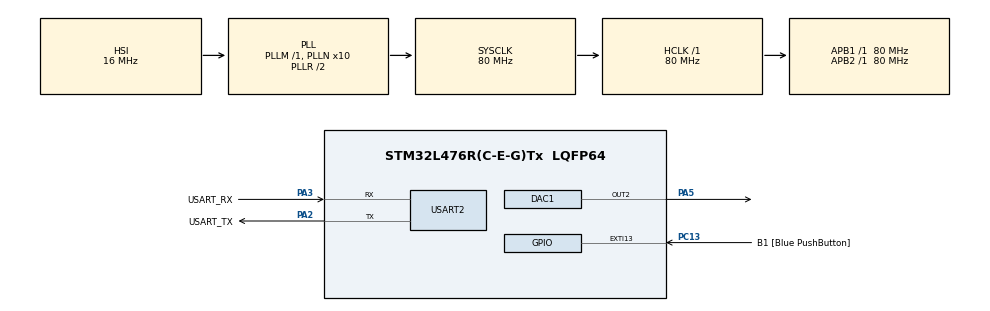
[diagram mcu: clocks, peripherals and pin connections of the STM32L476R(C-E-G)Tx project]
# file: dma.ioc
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DAC1.DAC_Channel-DAC_OUT2=DAC_CHANNEL_2
DAC1.DAC_Trigger-DAC_OUT2=DAC_TRIGGER_T6_TRGO
Dma.DAC_CH2.0.Direction=DMA_MEMORY_TO_PERIPH
Dma.DAC_CH2.0.Instance=DMA1_Channel4
Dma.DAC_CH2.0.MemDataAlignment=DMA_MDATAALIGN_BYTE
Dma.DAC_CH2.0.MemInc=DMA_MINC_ENABLE
Dma.DAC_CH2.0.Mode=DMA_CIRCULAR
Dma.DAC_CH2.0.PeriphDataAlignment=DMA_PDATAALIGN_BYTE
Dma.DAC_CH2.0.PeriphInc=DMA_PINC_DISABLE
Dma.DAC_CH2.0.Priority=DMA_PRIORITY_LOW
Dma.Request0=DAC_CH2
Mcu.Family=STM32L4
Mcu.Name=STM32L476R(C-E-G)Tx
Mcu.Package=LQFP64
NVIC.DMA1_Channel4_IRQn=true\:0\:0\:false\:false\:true\:false\:true
NVIC.PriorityGroup=NVIC_PRIORITYGROUP_4
NVIC.TIM6_DAC_IRQn=true\:0\:0\:false\:false\:true\:true\:true
PA13\ (JTMS-SWDIO).GPIO_Label=TMS
PA13\ (JTMS-SWDIO).Mode=Serial_Wire
PA13\ (JTMS-SWDIO).Signal=SYS_JTMS-SWDIO
PA14\ (JTCK-SWCLK).GPIO_Label=TCK
PA14\ (JTCK-SWCLK).Mode=Serial_Wire
PA14\ (JTCK-SWCLK).Signal=SYS_JTCK-SWCLK
PA2.GPIO_Label=USART_TX
PA2.GPIO_Mode=GPIO_MODE_AF_PP
PA2.GPIO_PuPd=GPIO_NOPULL
PA2.GPIO_Speed=GPIO_SPEED_FREQ_VERY_HIGH
PA2.Mode=Asynchronous
PA2.Signal=USART2_TX
PA3.GPIO_Label=USART_RX
PA3.GPIO_Mode=GPIO_MODE_AF_PP
PA3.GPIO_PuPd=GPIO_NOPULL
PA3.GPIO_Speed=GPIO_SPEED_FREQ_VERY_HIGH
PA3.Mode=Asynchronous
PA3.Signal=USART2_RX
PA5.Signal=COMP_DAC12_group
PB3\ (JTDO-TRACESWO).GPIO_Label=SWO
PB3\ (JTDO-TRACESWO).Signal=SYS_JTDO-SWO
PC13.GPIO_Label=B1 [Blue PushButton]
PC13.GPIO_ModeDefaultEXTI=GPIO_MODE_IT_FALLING
PC13.GPIO_PuPd=GPIO_NOPULL
PC13.Signal=GPXTI13
PC14-OSC32_IN\ (PC14).Mode=LSE-External-Oscillator
PC14-OSC32_IN\ (PC14).Signal=RCC_OSC32_IN
PC15-OSC32_OUT\ (PC15).Mode=LSE-External-Oscillator
PC15-OSC32_OUT\ (PC15).Signal=RCC_OSC32_OUT
PH0-OSC_IN\ (PH0).Signal=RCC_OSC_IN
PH1-OSC_OUT\ (PH1).Signal=RCC_OSC_OUT
ProjectManager.HeapSize=0x200
ProjectManager.StackSize=0x400
ProjectManager.TargetToolchain=STM32CubeIDE
RCC.ADCFreq_Value=64000000
RCC.AHBFreq_Value=80000000
RCC.APB1Freq_Value=80000000
RCC.APB1TimFreq_Value=80000000
RCC.APB2Freq_Value=80000000
RCC.APB2TimFreq_Value=80000000
RCC.CortexFreq_Value=80000000
RCC.HCLKFreq_Value=80000000
RCC.HSE_VALUE=8000000
RCC.HSI_VALUE=16000000
RCC.MSI_VALUE=4000000
RCC.PLLN=10
RCC.PLLSourceVirtual=RCC_PLLSOURCE_HSI
RCC.PREFETCH_ENABLE=1
RCC.SYSCLKFreq_VALUE=80000000
RCC.SYSCLKSource=RCC_SYSCLKSOURCE_PLLCLK
RCC.USBFreq_Value=64000000
RCC.VCOOutputFreq_Value=160000000
SH.COMP_DAC12_group.0=DAC1_OUT2,DAC_OUT2
TIM6.AutoReloadPreload=TIM_AUTORELOAD_PRELOAD_ENABLE
TIM6.Period=4999
TIM6.Prescaler=15999
TIM6.TIM_MasterOutputTrigger=TIM_TRGO_UPDATE
USART2.VirtualMode-Asynchronous=VM_ASYNC
VP_TIM6_VS_ClockSourceINT.Mode=Enable_Timer
board=NUCLEO-L476RG

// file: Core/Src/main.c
/* USER CODE BEGIN Header */
/**
  ******************************************************************************
  * @file           : main.c
  * @brief          : Main program body
  ******************************************************************************
  * @attention
  *
  * <h2><center>&copy; Copyright (c) 2021 STMicroelectronics.
  * All rights reserved.</center></h2>
  *
  * This software component is licensed by ST under BSD 3-Clause license,
  * the "License"; You may not use this file except in compliance with the
  * License. You may obtain a copy of the License at:
  *                        opensource.org/licenses/BSD-3-Clause
  *
  ******************************************************************************
  */
/* USER CODE END Header */
#include "main.h"

/* USER CODE BEGIN Includes */
#include <stdio.h>
/* USER CODE END Includes */

DAC_HandleTypeDef hdac1;
DMA_HandleTypeDef hdma_dac_ch2;
char dac[] = {128, 176, 217, 245, 255, 245, 217, 176, 128, 79, 38, 10, 1, 10, 38, 79};
TIM_HandleTypeDef htim6;

UART_HandleTypeDef huart2;

/* USER CODE BEGIN PV */
volatile uint8_t timINT;
/* USER CODE END PV */

void SystemClock_Config(void);
static void MX_GPIO_Init(void);
static void MX_DMA_Init(void);
static void MX_USART2_UART_Init(void);
static void MX_DAC1_Init(void);
static void MX_TIM6_Init(void);

/* USER CODE BEGIN 0 */
int _write(int file, char *ptr, int len) {
	HAL_UART_Transmit(&huart2, (uint8_t*)ptr, len, 50);
	return len;
}

void HAL_TIM_PeriodElapsedCallback(TIM_HandleTypeDef *htim) {
	if(htim == &htim6) {
		timINT = 1;
	}
}

/* USER CODE END 0 */

int main(void)
{
  /* USER CODE BEGIN 1 */

	//uint8_t dacValue[] = {0,39,77,116,154,193,231,255};
	uint8_t tab[] = {0,39,77,116,155,193,232,255};

  /* USER CODE END 1 */

  /* MCU Configuration--------------------------------------------------------*/

  /* Reset of all peripherals, Initializes the Flash interface and the Systick. */
  HAL_Init();

  /* Configure the system clock */
  SystemClock_Config();

  /* Initialize all configured peripherals */
  MX_GPIO_Init();
  MX_DMA_Init();
  MX_USART2_UART_Init();
  MX_DAC1_Init();
  MX_TIM6_Init();
  /* USER CODE BEGIN 2 */
//  HAL_DAC_Start(&hdac1, DAC_CHANNEL_2);
//  HAL_DAC_SetValue(&hdac1, DAC_CHANNEL_2, DAC_ALIGN_8B_R, 255);
  HAL_DAC_Start_DMA(&hdac1, DAC_CHANNEL_2, (uint32_t*)tab, 8, DAC_ALIGN_8B_R);
  HAL_TIM_Base_Start_IT(&htim6);
  /* USER CODE END 2 */

  /* Infinite loop */
  /* USER CODE BEGIN WHILE */
  while (1)
  {
	  if(timINT) {
		  timINT = 0;
		  printf("DAC %ld\r\n", HAL_DAC_GetValue(&hdac1, DAC_CHANNEL_2));
	  }
    /* USER CODE END WHILE */

  }
}

void SystemClock_Config(void)
{
  RCC_OscInitTypeDef RCC_OscInitStruct = {0};
  RCC_ClkInitTypeDef RCC_ClkInitStruct = {0};
  RCC_PeriphCLKInitTypeDef PeriphClkInit = {0};

  /** Initializes the RCC Oscillators according to the specified parameters
  * in the RCC_OscInitTypeDef structure.
  */
  RCC_OscInitStruct.OscillatorType = RCC_OSCILLATORTYPE_HSI;
  RCC_OscInitStruct.HSIState = RCC_HSI_ON;
  RCC_OscInitStruct.HSICalibrationValue = RCC_HSICALIBRATION_DEFAULT;
  RCC_OscInitStruct.PLL.PLLState = RCC_PLL_ON;
  RCC_OscInitStruct.PLL.PLLSource = RCC_PLLSOURCE_HSI;
  RCC_OscInitStruct.PLL.PLLM = 1;
  RCC_OscInitStruct.PLL.PLLN = 10;
  RCC_OscInitStruct.PLL.PLLP = RCC_PLLP_DIV7;
  RCC_OscInitStruct.PLL.PLLQ = RCC_PLLQ_DIV2;
  RCC_OscInitStruct.PLL.PLLR = RCC_PLLR_DIV2;
  if (HAL_RCC_OscConfig(&RCC_OscInitStruct) != HAL_OK)
  {
    Error_Handler();
  }
  /** Initializes the CPU, AHB and APB buses clocks
  */
  RCC_ClkInitStruct.ClockType = RCC_CLOCKTYPE_HCLK|RCC_CLOCKTYPE_SYSCLK
                              |RCC_CLOCKTYPE_PCLK1|RCC_CLOCKTYPE_PCLK2;
  RCC_ClkInitStruct.SYSCLKSource = RCC_SYSCLKSOURCE_PLLCLK;
  RCC_ClkInitStruct.AHBCLKDivider = RCC_SYSCLK_DIV1;
  RCC_ClkInitStruct.APB1CLKDivider = RCC_HCLK_DIV1;
  RCC_ClkInitStruct.APB2CLKDivider = RCC_HCLK_DIV1;

  if (HAL_RCC_ClockConfig(&RCC_ClkInitStruct, FLASH_LATENCY_4) != HAL_OK)
  {
    Error_Handler();
  }
  PeriphClkInit.PeriphClockSelection = RCC_PERIPHCLK_USART2;
  PeriphClkInit.Usart2ClockSelection = RCC_USART2CLKSOURCE_PCLK1;
  if (HAL_RCCEx_PeriphCLKConfig(&PeriphClkInit) != HAL_OK)
  {
    Error_Handler();
  }
  /** Configure the main internal regulator output voltage
  */
  if (HAL_PWREx_ControlVoltageScaling(PWR_REGULATOR_VOLTAGE_SCALE1) != HAL_OK)
  {
    Error_Handler();
  }
}

static void MX_DAC1_Init(void)
{

  DAC_ChannelConfTypeDef sConfig = {0};

  /** DAC Initialization
  */
  hdac1.Instance = DAC1;
  if (HAL_DAC_Init(&hdac1) != HAL_OK)
  {
    Error_Handler();
  }
  /** DAC channel OUT2 config
  */
  sConfig.DAC_SampleAndHold = DAC_SAMPLEANDHOLD_DISABLE;
  sConfig.DAC_Trigger = DAC_TRIGGER_T6_TRGO;
  sConfig.DAC_OutputBuffer = DAC_OUTPUTBUFFER_ENABLE;
  sConfig.DAC_ConnectOnChipPeripheral = DAC_CHIPCONNECT_DISABLE;
  sConfig.DAC_UserTrimming = DAC_TRIMMING_FACTORY;
  if (HAL_DAC_ConfigChannel(&hdac1, &sConfig, DAC_CHANNEL_2) != HAL_OK)
  {
    Error_Handler();
  }

}

static void MX_TIM6_Init(void)
{

  TIM_MasterConfigTypeDef sMasterConfig = {0};

  htim6.Instance = TIM6;
  htim6.Init.Prescaler = 15999;
  htim6.Init.CounterMode = TIM_COUNTERMODE_UP;
  htim6.Init.Period = 4999;
  htim6.Init.AutoReloadPreload = TIM_AUTORELOAD_PRELOAD_DISABLE;
  if (HAL_TIM_Base_Init(&htim6) != HAL_OK)
  {
    Error_Handler();
  }
  sMasterConfig.MasterOutputTrigger = TIM_TRGO_UPDATE;
  sMasterConfig.MasterSlaveMode = TIM_MASTERSLAVEMODE_DISABLE;
  if (HAL_TIMEx_MasterConfigSynchronization(&htim6, &sMasterConfig) != HAL_OK)
  {
    Error_Handler();
  }

}

static void MX_USART2_UART_Init(void)
{

  huart2.Instance = USART2;
  huart2.Init.BaudRate = 115200;
  huart2.Init.WordLength = UART_WORDLENGTH_8B;
  huart2.Init.StopBits = UART_STOPBITS_1;
  huart2.Init.Parity = UART_PARITY_NONE;
  huart2.Init.Mode = UART_MODE_TX_RX;
  huart2.Init.HwFlowCtl = UART_HWCONTROL_NONE;
  huart2.Init.OverSampling = UART_OVERSAMPLING_16;
  huart2.Init.OneBitSampling = UART_ONE_BIT_SAMPLE_DISABLE;
  huart2.AdvancedInit.AdvFeatureInit = UART_ADVFEATURE_NO_INIT;
  if (HAL_UART_Init(&huart2) != HAL_OK)
  {
    Error_Handler();
  }

}

static void MX_DMA_Init(void)
{

  /* DMA controller clock enable */
  __HAL_RCC_DMA1_CLK_ENABLE();

  /* DMA interrupt init */
  /* DMA1_Channel4_IRQn interrupt configuration */
  HAL_NVIC_SetPriority(DMA1_Channel4_IRQn, 0, 0);
  HAL_NVIC_EnableIRQ(DMA1_Channel4_IRQn);

}

static void MX_GPIO_Init(void)
{
  GPIO_InitTypeDef GPIO_InitStruct = {0};

  /* GPIO Ports Clock Enable */
  __HAL_RCC_GPIOC_CLK_ENABLE();
  __HAL_RCC_GPIOH_CLK_ENABLE();
  __HAL_RCC_GPIOA_CLK_ENABLE();
  __HAL_RCC_GPIOB_CLK_ENABLE();

  /*Configure GPIO pin : B1_Pin */
  GPIO_InitStruct.Pin = B1_Pin;
  GPIO_InitStruct.Mode = GPIO_MODE_IT_FALLING;
  GPIO_InitStruct.Pull = GPIO_NOPULL;
  HAL_GPIO_Init(B1_GPIO_Port, &GPIO_InitStruct);

}

void Error_Handler(void)
{
}

/************************ (C) COPYRIGHT STMicroelectronics *****END OF FILE****/
